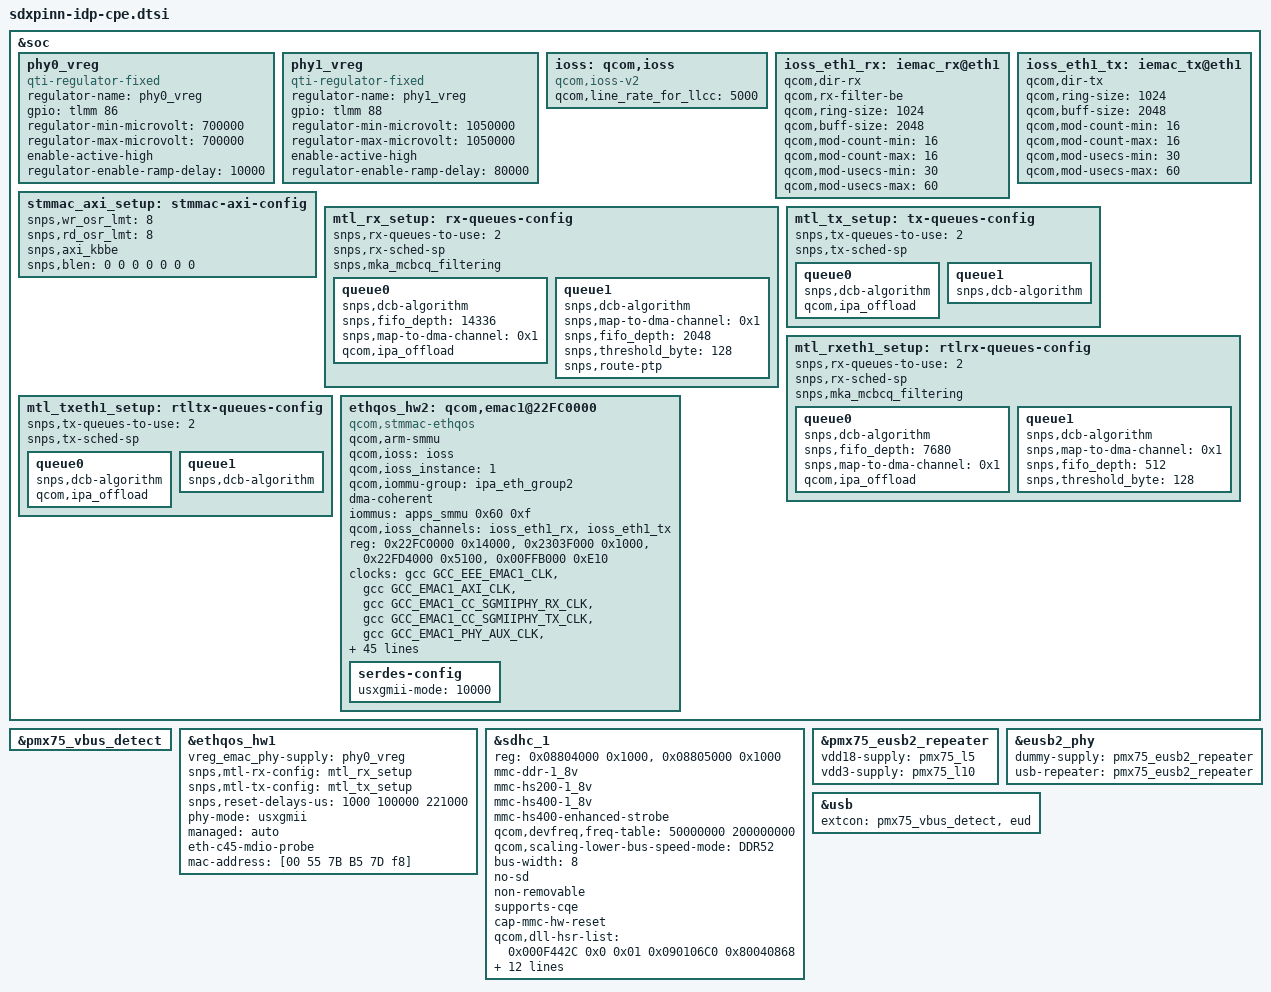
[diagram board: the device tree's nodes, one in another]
#include <dt-bindings/gpio/gpio.h>

#include "sdxpinn-pmic-overlay.dtsi"
#include "sdxpinn-qcn9224.dtsi"

&soc {
	phy0_vreg: phy0_vreg {
		compatible = "qti-regulator-fixed";
		regulator-name = "phy0_vreg";
		gpio = <&tlmm 86 GPIO_ACTIVE_HIGH>;
		regulator-min-microvolt = <700000>;
		regulator-max-microvolt = <700000>;
		enable-active-high;
		regulator-enable-ramp-delay = <10000>;
	};

	phy1_vreg: phy1_vreg {
		compatible = "qti-regulator-fixed";
		regulator-name = "phy1_vreg";
		gpio = <&tlmm 88 GPIO_ACTIVE_HIGH>;
		regulator-min-microvolt = <1050000>;
		regulator-max-microvolt = <1050000>;
		enable-active-high;
		regulator-enable-ramp-delay = <80000>;
	};

	ioss: qcom,ioss {
		compatible = "qcom,ioss-v2";
		qcom,line_rate_for_llcc = <5000>;
	};

	ioss_eth1_rx: iemac_rx@eth1 {
		qcom,dir-rx;
		qcom,rx-filter-be;

		qcom,ring-size = <1024>;
		qcom,buff-size = <2048>;

		qcom,mod-count-min = <16>;
		qcom,mod-count-max = <16>;
		qcom,mod-usecs-min = <30>;
		qcom,mod-usecs-max = <60>;
	};

	ioss_eth1_tx: iemac_tx@eth1 {
		qcom,dir-tx;
		qcom,ring-size = <1024>;
		qcom,buff-size = <2048>;

		qcom,mod-count-min = <16>;
		qcom,mod-count-max = <16>;
		qcom,mod-usecs-min = <30>;
		qcom,mod-usecs-max = <60>;
	};

	stmmac_axi_setup: stmmac-axi-config {
		snps,wr_osr_lmt = <8>;
		snps,rd_osr_lmt = <8>;
		snps,axi_kbbe;
		/* If FB is disabled, the AXI master chooses
		 * a burst length of any value less than the
		 * maximum enabled burst length
		 * (all lesser burst length enables are redundant).
		 */
		snps,blen = <0 0 0 0 0 0 0>;
	};

	mtl_rx_setup: rx-queues-config {
		snps,rx-queues-to-use = <2>;
		snps,rx-sched-sp;
		snps,mka_mcbcq_filtering;

		queue0 {
			snps,dcb-algorithm;
			snps,fifo_depth = <14336>;
			snps,map-to-dma-channel = <0x1>;
			qcom,ipa_offload;
		};

		queue1 {
			snps,dcb-algorithm;
			snps,map-to-dma-channel = <0x1>;
			snps,fifo_depth = <2048>;
			snps,threshold_byte = <128>;
			snps,route-ptp;
		};
	};

	mtl_tx_setup: tx-queues-config {
		snps,tx-queues-to-use = <2>;
		snps,tx-sched-sp;
		queue0 {
			snps,dcb-algorithm;
			qcom,ipa_offload;
		};

		queue1 {
			snps,dcb-algorithm;
		};
	};

	mtl_rxeth1_setup: rtlrx-queues-config {
		snps,rx-queues-to-use = <2>;
		snps,rx-sched-sp;
		snps,mka_mcbcq_filtering;

		queue0 {
			snps,dcb-algorithm;
			snps,fifo_depth = <7680>;
			snps,map-to-dma-channel = <0x1>;
			qcom,ipa_offload;
		};

		queue1 {
			snps,dcb-algorithm;
			snps,map-to-dma-channel = <0x1>;
			snps,fifo_depth = <512>;
			snps,threshold_byte = <128>;
		};
	};

	mtl_txeth1_setup: rtltx-queues-config {
		snps,tx-queues-to-use = <2>;
		snps,tx-sched-sp;
		queue0 {
			snps,dcb-algorithm;
			qcom,ipa_offload;
		};

		queue1 {
			snps,dcb-algorithm;
		};
	};

	ethqos_hw2: qcom,emac1@22FC0000 {
		compatible = "qcom,stmmac-ethqos", "snps,dwxgmac","qcom,ioss-v2-device";
		qcom,arm-smmu;
		qcom,ioss = <&ioss>;
		qcom,ioss_instance = <1>;
		qcom,iommu-group = <&ipa_eth_group2>;
		dma-coherent;
		iommus = <&apps_smmu 0x60 0xf>;

		qcom,ioss_channels =
			<&ioss_eth1_rx>,
			<&ioss_eth1_tx>;

		reg = <0x22FC0000 0x14000>,
			<0x2303F000 0x1000>,
			<0x22FD4000 0x5100>,
			<0x00FFB000 0xE10>;
		reg-names = "stmmaceth", "rgmii","xpcs","serdes";
		clocks = <&gcc GCC_EEE_EMAC1_CLK>,
			<&gcc GCC_EMAC1_AXI_CLK>,
			<&gcc GCC_EMAC1_CC_SGMIIPHY_RX_CLK>,
			<&gcc GCC_EMAC1_CC_SGMIIPHY_TX_CLK>,
			<&gcc GCC_EMAC1_PHY_AUX_CLK>,
			<&gcc GCC_EMAC1_RPCS_RX_CLK>,
			<&gcc GCC_EMAC1_RPCS_TX_CLK>,
			<&gcc GCC_EMAC1_SLV_AHB_CLK>,
			<&gcc GCC_EMAC1_XGXS_RX_CLK>,
			<&gcc GCC_EMAC1_XGXS_TX_CLK>,
			<&gcc GCC_EMAC1_CC_SGMIIPHY_RX_CLK_SRC>,
			<&gcc GCC_EMAC1_CC_SGMIIPHY_TX_CLK_SRC>,
			<&gcc GCC_EMAC1_SGMIIPHY_MAC_RCLK_SRC>,
			<&gcc GCC_EMAC1_SGMIIPHY_MAC_TCLK_SRC>,
			<&emac1_sgmiiphy_rclk>,
			<&emac1_sgmiiphy_tclk>,
			<&emac1_sgmiiphy_mac_rclk>,
			<&emac1_sgmiiphy_mac_tclk>,
			<&gcc GCC_EMAC_1_CLKREF_EN>;
		clock-names = "eee", "stmmaceth", "sgmii_rx",
		"sgmii_tx", "phyaux",
		"pcs_rx", "pcs_tx", "pclk", "xgxs_rx",
		"xgxs_tx", "sgmii_rclk_src", "sgmii_tclk_src",
		"sgmii_mac_rclk_src", "sgmii_mac_tclk_src", "sgmii_rclk",
		"sgmii_tclk", "sgmii_mac_rclk", "sgmii_mac_tclk","sgmi_ref";

		interrupts-extended = <&intc GIC_SPI 445 IRQ_TYPE_LEVEL_HIGH>, <&tlmm 109 IRQ_TYPE_EDGE_FALLING>;

		interrupt-names = "macirq", "phy-intr";

		vreg_a_sgmii_1p2-supply = <&L1B>;
		vreg_a_sgmii_0p9-supply = <&L4B>;
		gdsc_emac-supply = <&gcc_emac1_gdsc>;
		pinctrl-names = "dev-emac1_mdc","dev-emac1_mdio","dev-emac1_pin_phy_intr",
		"dev-emac1_phy_reset_state";
		pinctrl-0 = <&emac1_mdc>;
		pinctrl-1 = <&emac1_mdio>;
		pinctrl-2 = <&emac1_pin_phy_intr>;
		pinctrl-3 = <&emac1_phy_reset_state>;

		vreg_emac_phy-supply = <&phy1_vreg>;
		qcom,phy-intr-redirect = <&tlmm 109 IRQ_TYPE_EDGE_FALLING>;
		snps,reset-gpio = <&tlmm 108 1>;
		snps,crc_strip;

		interconnect-names = "axi_icc_path", "apb_icc_path";
		interconnects = <&system_noc MASTER_EMAC_1 &mc_virt SLAVE_EBI1>,
				<&gem_noc MASTER_APPSS_PROC &system_noc SLAVE_ETH1_CFG>;

		snps,tso;
		snps,pbl = <32>;
		rx-fifo-depth = <8192>;
		tx-fifo-depth = <16384>;
		snps,mtl-rx-config = <&mtl_rxeth1_setup>;
		snps,mtl-tx-config = <&mtl_txeth1_setup>;

		snps,reset-active-low;
		snps,reset-delays-us = <1000 40 150000>;
		phy-mode = "usxgmii";
		managed = "auto";
		eth-c45-mdio-probe;
		snps,axi-config = <&stmmac_axi_setup>;
		mac-address = [00 55 7B B5 7D f7];
		serdes-config {
			/* Valid values for usxgmii-mode:
			 * 10000: 10G mode
			 * 5000: 5G mode
			 * 2500: 2.5G mode
			 */
			usxgmii-mode = <10000>;
		};

	};
};

&pmx75_vbus_detect {
	status = "ok";
};

&ethqos_hw1 {
	vreg_emac_phy-supply = <&phy0_vreg>;
	snps,mtl-rx-config = <&mtl_rx_setup>;
	snps,mtl-tx-config = <&mtl_tx_setup>;

	snps,reset-delays-us = <1000 100000 221000>;
	phy-mode = "usxgmii";
	managed = "auto";
	eth-c45-mdio-probe;
	mac-address = [00 55 7B B5 7D f8];
};

&sdhc_1 {
	status = "ok";

	reg = <0x08804000 0x1000>, <0x08805000 0x1000>;
	reg-names = "hc", "cqhci";

	mmc-ddr-1_8v;
	mmc-hs200-1_8v;
	mmc-hs400-1_8v;
	mmc-hs400-enhanced-strobe;

	qcom,devfreq,freq-table = <50000000 200000000>;
	qcom,scaling-lower-bus-speed-mode = "DDR52";

	bus-width = <8>;
	no-sd;
	non-removable;
	supports-cqe;
	cap-mmc-hw-reset;

	/* DLL HSR settings. Refer go/hsr - <Target> DLL settings */
	qcom,dll-hsr-list = <0x000F442C 0x0 0x01
				0x090106C0 0x80040868>;

	/* Add dt entry for gcc hw reset */
	resets = <&gcc GCC_EMMC_BCR>;
	reset-names = "core_reset";

	vdd-supply = <&vreg_sdc1_emmc_sd_vdd>;
	qcom,vdd-voltage-level = <2950000 2950000>;
	qcom,vdd-current-level = <0 570000>;

	vdd-io-supply = <&L6B>;
	qcom,vdd-io-always-on;
	qcom,vdd-io-lpm-sup;
	qcom,vdd-io-voltage-level = <1800000 1800000>;
	qcom,vdd-io-current-level = <0 200000>;

	pinctrl-names = "default", "sleep";
	pinctrl-0 = <&sdc1_emmc_on>;
	pinctrl-1 = <&sdc1_emmc_off>;

	operating-points-v2 = <&sdhc1_opp_table>;
};

&pmx75_eusb2_repeater {
	vdd18-supply = <&pmx75_l5>;
	vdd3-supply = <&pmx75_l10>;
	status = "ok";
};

&eusb2_phy {
	dummy-supply = <&pmx75_eusb2_repeater>;
	usb-repeater = <&pmx75_eusb2_repeater>;
};

&usb {
	extcon = <&pmx75_vbus_detect>, <&eud>;
};
